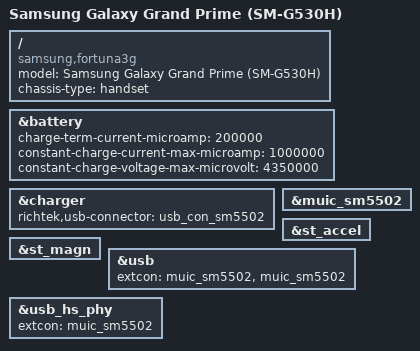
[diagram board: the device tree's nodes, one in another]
// SPDX-License-Identifier: GPL-2.0-only

/dts-v1/;

#include "msm8916-samsung-fortuna-common.dtsi"

/ {
	model = "Samsung Galaxy Grand Prime (SM-G530H)";
	compatible = "samsung,fortuna3g", "qcom,msm8916";
	chassis-type = "handset";
};

&battery {
	charge-term-current-microamp = <200000>;
	constant-charge-current-max-microamp = <1000000>;
	constant-charge-voltage-max-microvolt = <4350000>;
};

&charger {
	richtek,usb-connector = <&usb_con_sm5502>;
	status = "okay";
};

&muic_sm5502 {
	status = "okay";
};

&st_accel {
	status = "okay";
};

&st_magn {
	status = "okay";
};

&usb {
	extcon = <&muic_sm5502>, <&muic_sm5502>;
	status = "okay";
};

&usb_hs_phy {
	extcon = <&muic_sm5502>;
};
